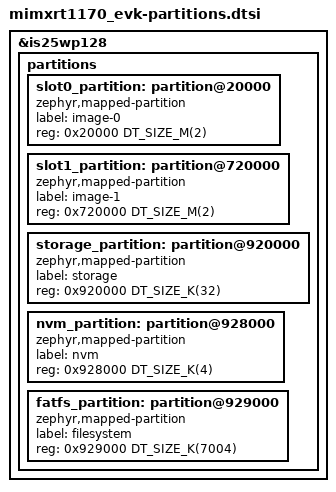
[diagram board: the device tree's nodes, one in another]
/* Partition layout for mimxrt1170_evk: the flash memory map shared by the
 * bootloader and every application image. Generated by
 * tools/partition_layout.py; do not edit by hand -- re-run
 * `python3 tools/partition_layout.py --fix mimxrt1170_evk` after changing
 * the upstream board geometry or tools/boards.toml.
 *
 * Board-specific overlay glue (delete-nodes, device enablement,
 * aliases/chosen) lives in dts/nxp/mimxrt1170_evk.dtsi, which includes
 * this file.
 */

&is25wp128 {
	partitions {

		/* Inherited from the upstream board dts and kept as-is
		 * (not re-emitted here):
		 *   mcuboot (boot_partition): 0x0 + DT_SIZE_K(128)
		 */

		slot0_partition: partition@20000 {
			compatible = "zephyr,mapped-partition";
			label = "image-0";
			reg = <0x20000 DT_SIZE_M(2)>;
		};

		slot1_partition: partition@720000 {
			compatible = "zephyr,mapped-partition";
			label = "image-1";
			reg = <0x720000 DT_SIZE_M(2)>;
		};

		storage_partition: partition@920000 {
			compatible = "zephyr,mapped-partition";
			label = "storage";
			reg = <0x920000 DT_SIZE_K(32)>;
		};

		nvm_partition: partition@928000 {
			compatible = "zephyr,mapped-partition";
			label = "nvm";
			reg = <0x928000 DT_SIZE_K(4)>;
		};

		fatfs_partition: partition@929000 {
			compatible = "zephyr,mapped-partition";
			label = "filesystem";
			reg = <0x929000 DT_SIZE_K(7004)>;
		};
	};
};
